# UART0 register map
Vendor: Texas Instruments
Peripheral module from a debugger description file (folder J7VCL).
Registers are 32-bit, access per field, reset 0x0 unless marked. A register's access mark holds for its fields unless they carry their own. Offsets are as the file gives them; lines under a group give offsets from that group; [hi:lo] are bit positions; {n}, {i} and the like mark numbered series; 'fields as' and 'values as' point back to an identical list; <NAME> marks a mode.

## UART0
0x00 UART_DLL — This register, with , stores the 14-bit divisor for generation of the baud clock in the baud rate generator. stores the most-significant part of the divisor. stores the least-significant part of the divisor.
  [7:0] CLOCK_LSB rw — Stores the 8-bit LSB divisor value
0x00 UART_RHR ro — The receiver section consists of the receiver holding register () and the receiver shift register. The is a 64-byte FIFO. The receiver shift register receives serial data from RX input. The data is converted to parallel data and moved to the . If the FIFO is disabled, location 0 of the FIFO stores the single data character. Note: If an overflow occurs, the data in the is not overwritten.
  [7:0] RHR — Receive holding register
0x00 UART_THR — The transmitter section consists of the transmit holding register () and the transmit shift register. The is a 64-byte FIFO. The local host (LH) writes data to the . The data is placed in the transmit shift register where it is shifted out serially on the TX output. If the FIFO is disabled, location 0 of the FIFO stores the data.
  [7:0] THR wo — Transmit holding register
0x04 UART_DLH — This register, with , stores the 14-bit divisor for generating the baud clock in the baud rate generator. DLH stores the most-significant part of the divisor. DLL stores the least-significant part of the divisor.
  [7:0] CLOCK_MSB rw — Stores the 8-bit MSB divisor value
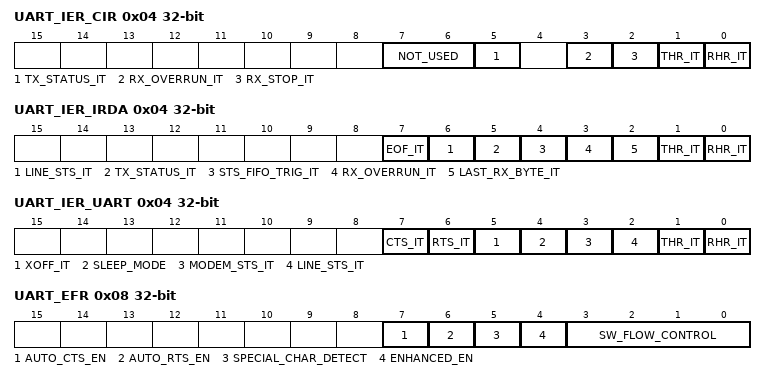
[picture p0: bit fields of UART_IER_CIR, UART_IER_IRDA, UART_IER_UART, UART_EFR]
0x04 UART_IER_CIR — There are 6 types of interrupt in these modes, TX status, status FIFO interrupt, RX overrun, last byte in RX FIFO, THR interrupt and RHR interrupt and they can be enabled/disabled individually. Notes: The RX_STOP_IT interrupt is generated based on the value set in the BOF Length register (). In IR-CIR mode, contrary to the IR-IRDA mode, the TX_STATUS_IT has only one meaning corresponding to the case [0] = 0.
  [7:6] NOT_USED rw, [5] TX_STATUS_IT rw, [3] RX_OVERRUN_IT rw, [2] RX_STOP_IT rw, [1] THR_IT rw, [0] RHR_IT rw
0x04 UART_IER_IRDA — There are 8 types of interrupt in these modes, received EOF, LSR interrupt, TX status, status FIFO interrupt, RX overrun, last byte in RX FIFO, THR interrupt and RHR interrupt and they can be enabled/disabled individually. Note: The TX_STATUS_IT interrupt reflects two possible conditions. The [0] should be read to determine the status in the event of this interrupt.
  [7] EOF_IT rw, [6] LINE_STS_IT rw, [5] TX_STATUS_IT rw, [4] STS_FIFO_TRIG_IT rw, [3] RX_OVERRUN_IT rw, [2] LAST_RX_BYTE_IT rw, [1] THR_IT rw, [0] RHR_IT rw
0x04 UART_IER_UART — Interrupt enable register The interrupt enable register () can be programmed to enable/disable any interrupt. There are seven types of interrupt in this mode: receiver error, interrupt, interrupt, XOFF received and CTS*/RTS* change of state from low to high. Each interrupt can be enabled/disabled individually. There is also a sleep mode enable bit.
  [7] CTS_IT rw, [6] RTS_IT rw, [5] XOFF_IT rw, [4] SLEEP_MODE rw, [3] MODEM_STS_IT rw, [2] LINE_STS_IT rw, [1] THR_IT rw, [0] RHR_IT rw
0x08 UART_EFR — Enhanced feature register This register enables or disables enhanced features. Most of the enhanced functions apply only to UART modes, but [4] enables write accesses to [5:4], the TX trigger level, which is also used in IrDA modes.
  [7] AUTO_CTS_EN rw — Auto-CTS enable bit
  [6] AUTO_RTS_EN rw — Auto-RTS enable bit
  [5] SPECIAL_CHAR_DETECT rw
  [4] ENHANCED_EN rw — Enhanced functions write enable bit
  [3:0] SW_FLOW_CONTROL rw — Combinations of software flow control can be selected by programming bit 3 - bit 0. See
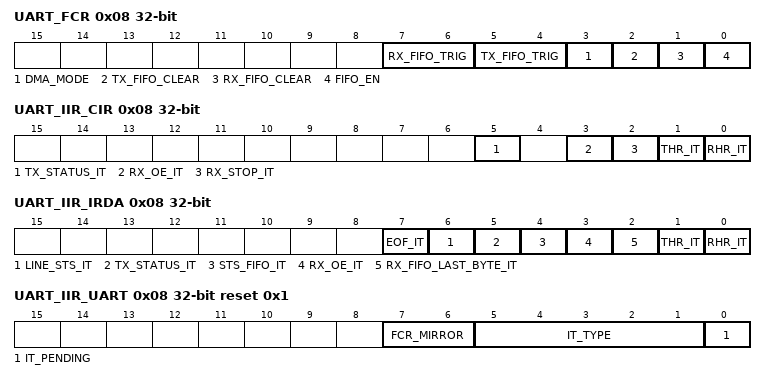
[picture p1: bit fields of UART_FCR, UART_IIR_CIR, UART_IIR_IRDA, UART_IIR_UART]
0x08 UART_FCR — FIFO control register Notes: Bits 4 and 5 can only be written to when [4] = 1. Bits 0 and 3 can be changed only when the baud clock is not running (DLL and DLH set to 0). See for [5:4] setting restriction when [6] = 1. See for [7:6] setting restriction when [7] = 1.
  [7:6] RX_FIFO_TRIG wo — Sets the trigger level for the RX FIFO: If
  [5:4] TX_FIFO_TRIG wo — Sets the trigger level for the TX FIFO: If
  [3] DMA_MODE wo — This register is considered if
  [2] TX_FIFO_CLEAR wo
  [1] RX_FIFO_CLEAR wo
  [0] FIFO_EN wo
0x08 UART_IIR_CIR ro — The interrupt line is activated whenever one of the 6 interrupts is active.
  [5] TX_STATUS_IT — Read 0h = TX status interrupt inactive
  [3] RX_OE_IT — Read 0h = RX overrun interrupt inactive
  [2] RX_STOP_IT — Read 0h = Receive stop interrupt inactive
  [1] THR_IT — Read 0h = THR interrupt inactive
  [0] RHR_IT — Read 0h = RHR interrupt inactive
0x08 UART_IIR_IRDA ro — The interrupt line is activated whenever one of the 8 interrupts is active.
  [7] EOF_IT, [6] LINE_STS_IT, [5] TX_STATUS_IT, [4] STS_FIFO_IT, [3] RX_OE_IT, [2] RX_FIFO_LAST_BYTE_IT, [1] THR_IT, [0] RHR_IT
0x08 UART_IIR_UART ro reset 0x1 — Interrupt identification register. The is a read-only register that provides the source of the interrupt in a prioritized manner.
  [7:6] FCR_MIRROR — Mirror the contents of
  [5:1] IT_TYPE — Read 0h = Modem interrupt. Priority = 4
  [0] IT_PENDING — Read 0h = An interrupt is pending.
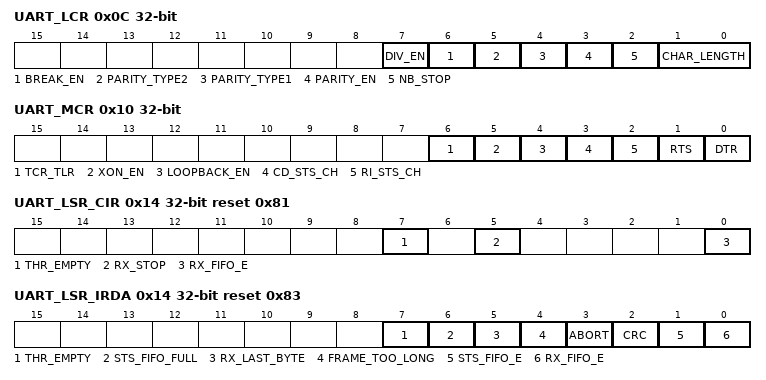
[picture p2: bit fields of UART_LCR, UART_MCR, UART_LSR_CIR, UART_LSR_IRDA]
0x0C UART_LCR — Line control register [6:0] define transmission and reception parameters. Note: When [6] is set to 1, the TX line is forced to 0 and remains in this state as long as [6] = 1.
  [7] DIV_EN rw
  [6] BREAK_EN rw — Break control bit
  [5] PARITY_TYPE2 rw — Selects the forced parity format (if
  [4] PARITY_TYPE1 rw
  [3] PARITY_EN rw — 0h = No parity
  [2] NB_STOP rw — Specifies the number of stop-bits
  [1:0] CHAR_LENGTH rw — Specifies the word length to be transmitted or received
0x10 UART_MCR — Modem control register [3:0] controls the interface with the modem, data set, or peripheral device that emulates the modem.
  [6] TCR_TLR rw — 0h = No action
  [5] XON_EN rw — 0h = Disable XON any function.
  [4] LOOPBACK_EN rw — 0h = Normal operating mode
  [3] CD_STS_CH rw — 0h = In loopback, forces DCD* input high and IRQ outputs to inactive state
  [2] RI_STS_CH rw — 0h = In loopback, forces RI* input high
  [1] RTS rw — In loopback, controls the
  [0] DTR rw — 0h = Force DTR* output to inactive (high).
0x10 UART_XON1_ADDR1 — UART mode: XON1 character, IrDA mode: ADDR1 address
  [7:0] XON_WORD1 rw — Stores the 8-bit XON1 character in UART modes and ADDR1 address 1 for IrDA modes
0x14 UART_LSR_CIR ro reset 0x81 — Line status register in CIR mode
  [7] THR_EMPTY — Read 0h = Transmit holding register (TX FIFO) is not empty.
  [5] RX_STOP — The RX_STOP is generated based on the value set in the BOF Length register (
  [0] RX_FIFO_E — Read 0h = At least one data character in the RX FIFO
0x14 UART_LSR_IRDA ro reset 0x83 — When the LSR is read, LSR[4:2] reflect the error bits [FL, CRC, ABORT] of the frame at the top of the STATUS FIFO (next frame status to be read).
  [7] THR_EMPTY — Read 0h = Transmit holding register (TX FIFO) is not empty.
  [6] STS_FIFO_FULL — Read 0h = Status FIFO not full
  [5] RX_LAST_BYTE — Read 0h = The RX FIFO (RHR) does not contain the last byte of the frame to be read.
  [4] FRAME_TOO_LONG — Read 0h = No frame-too-long error in frame
  [3] ABORT — Read 0h = No abort pattern error in frame
  [2] CRC — Read 0h = No CRC error in frame
  [1] STS_FIFO_E — Read 0h = Status FIFO not empty
  [0] RX_FIFO_E — Read 0h = No data in the RX FIFO
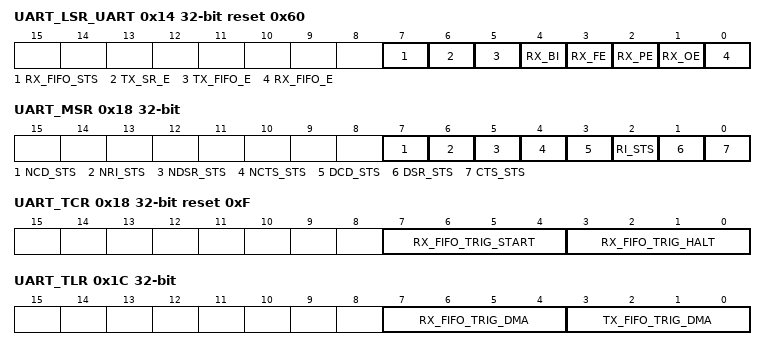
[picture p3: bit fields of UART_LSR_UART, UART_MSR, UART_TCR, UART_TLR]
0x14 UART_LSR_UART ro reset 0x60 — Line status register
  [7] RX_FIFO_STS — Read 0h = Normal operation
  [6] TX_SR_E — Read 0h = Transmitter hold (TX FIFO) and shift registers are not empty.
  [5] TX_FIFO_E — Read 0h = Transmit hold register (TX FIFO) is not empty.
  [4] RX_BI — Read 0h = No break condition
  [3] RX_FE — Read 0h = No framing error in data RX FIFO
  [2] RX_PE — Read 0h = No parity error in data from RX FIFO
  [1] RX_OE — Read 0h = No overrun error
  [0] RX_FIFO_E — Read 0h = No data in the RX FIFO
0x14 UART_XON2_ADDR2 — Stores the 8-bit XON2 character in UART moldes and ADDR2 address 2 for IrDA modes
  [7:0] XON_WORD2 rw — Stores the 8-bit XON2 character in UART modes and ADDR2 address 2 for IrDA modes
0x18 UART_MSR ro — Modem status register. UART mode only. This register provides information about the current state of the control lines from the modem, data set, or peripheral device to the LH. It also indicates when a control input from the modem changes state.
  [7] NCD_STS — This bit is the complement of the DCD* input. In loopback mode, it is equivalent to
  [6] NRI_STS — This bit is the complement of the RI* input. In loopback mode, it is equivalent to
  [5] NDSR_STS — This bit is the complement of the DSR* input. In loopback mode, it is equivalent to
  [4] NCTS_STS — This bit is the complement of the CTS* input. In loopback mode, it is equivalent to
  [3] DCD_STS — Indicates that DCD* input (or
  [2] RI_STS — Indicates that RI* input (or
  [1] DSR_STS
  [0] CTS_STS
0x18 UART_TCR reset 0xF — Transmission control register This register stores the RX FIFO threshold levels to start/stop transmission during hardware/software flow control. Notes: Trigger levels from 0 to 60 bytes are available with a granularity of 4. (Trigger level = 4 x [4-bit register value]) The programmer must ensure that [3:0] > [7:4] when auto-RTS or software flow control is enabled to avoid a mis-operation of the device. In FIFO interrupt mode with flow control, the programmer must ensure that the trigger level to halt transmission is greater than or equal to the RX FIFO trigger level ([7:4] or [7:6]); otherwise, FIFO operation stalls. In FIFO DMA mode with flow control, this concept does not exist because a DMA request is sent each time a byte is received.
  [7:4] RX_FIFO_TRIG_START rw — RX FIFO trigger level to RESTORE transmission (0 - 60)
  [3:0] RX_FIFO_TRIG_HALT rw — RX FIFO trigger level to HALT transmission (0 - 60)
0x18 UART_XOFF1 — UART mode XOFF1 character
  [7:0] XOFF_WORD1 rw — Stores the 8-bit XOFF1 character used in UART modes
0x1C UART_SPR — Scratchpad register This read/write register does not control the module. It is a scratchpad register to be used by the programmer to hold temporary data.
  [7:0] SPR_WORD rw — Scratchpad register
0x1C UART_TLR — Trigger level register This register stores the programmable transmit and RX FIFO trigger levels for DMA and IRQ generation.
  [7:4] RX_FIFO_TRIG_DMA rw — Receive FIFO trigger level
  [3:0] TX_FIFO_TRIG_DMA rw — Transmit FIFO trigger level
0x1C UART_XOFF2 — UART mode XOFF2 character
  [7:0] XOFF_WORD2 rw — Stores the 8-bit XOFF2 character used in UART modes.
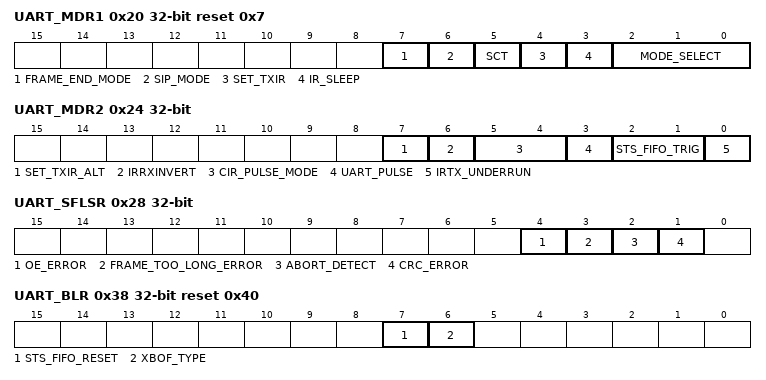
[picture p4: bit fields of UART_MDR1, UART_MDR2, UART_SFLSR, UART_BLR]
0x20 UART_MDR1 reset 0x7 — Mode definition register 1 The mode of operation can be programmed by writing to MDR1[2:0] and therefore the must be programmed on startup after configuration of the configuration registers (, , and ). The value of MDR1[2:0] must not be changed again during normal operation. Note: If the module is disabled by setting the MODE_SELECT field to 111, interrupt requests can still be generated unless disabled through the interrupt enable register (UART_IER). In this case, UART mode interrupts are visible. Reading the interrupt identification register (UART_IIR) shows UART mode interrupt flags.
  [7] FRAME_END_MODE rw — IrDA mode only
  [6] SIP_MODE rw — MIR/FIR modes only
  [5] SCT rw — Store and control the transmission.
  [4] SET_TXIR rw — Used to configure the infrared transceiver
  [3] IR_SLEEP rw — 0h = IrDA/CIR sleep mode disabled
  [2:0] MODE_SELECT rw — 0h = UART 16x mode
0x24 UART_MDR2 — Mode definition register 2 IR-IrDA and IR-CIR modes only. [0] describes the status of the interrupt in UART_IIR[5]. The IRTX_UNDERRUN bit should be read after an UART_IIR[5] TX_STATUS_IT interrupt. The bits [2:1] of this register set the trigger level for the frame status FIFO (8 entries) and must be programmed before the mode is programmed in [2:0]. Note: The [6] gives the flexibility to invert the RX pin in the UART to ensure that the protocol at the input of the transceiver module has the same polarity at module level. By default, the RX pin is inverted because most transceivers invert the IR receive pin.
  [7] SET_TXIR_ALT rw — Provide alternate function for
  [6] IRRXINVERT rw — IR mode only (IrDA and CIR). Invert RX pin in the module before the voting or sampling system logic of the infrared block. This does not affect the RX path in UART modem modes.
  [5:4] CIR_PULSE_MODE rw — CIR pulse modulation definition. Defines high level of the pulse width associated with a digit:
  [3] UART_PULSE rw — UART mode only. Allows pulse shaping in UART mode.
  [2:1] STS_FIFO_TRIG rw — IR-IrDA mode only. Frame status FIFO threshold select:
  [0] IRTX_UNDERRUN ro — IrDA transmission status interrupt. When the UART_IIR[5] interrupt occurs, the meaning of the interrupt is:
0x28 UART_SFLSR ro — Status FIFO line status register IrDA modes only. Reading this register effectively reads frame status information from the status FIFO (this register does not physically exist). Reading this register increments the status FIFO read pointer ( and must be read first).
  [4] OE_ERROR — Read 1h = Overrun error in RX FIFO when frame at top of RX FIFO was received
  [3] FRAME_TOO_LONG_ERROR — Read 1h = Frame-length too long error in frame at top of RX FIFO
  [2] ABORT_DETECT — Read 1h = Abort pattern detected in frame at top of RX FIFO
  [1] CRC_ERROR — Read 1h = CRC error in frame at top of RX FIFO
0x28 UART_TXFLL — Transmit frame length register low IrDA modes only. The and registers hold the 13-bit transmit frame length (expressed in bytes). holds the LSBs and holds the MSBs. The frame length value is used if the frame length method of frame closing is used.
  [7:0] TXFLL wo — LSB register used to specify the frame length
0x2C UART_RESUME ro — IR-IrDA and IR-CIR modes only. This register is used to clear internal flags, which halt transmission/reception when an underrun/overrun error occurs. Reading this register resumes the halted operation. This register does not physically exist and reads always as 0x00.
  [7:0] RESUME — Dummy read to restart the TX or RX
0x2C UART_TXFLH — Transmit frame length register high IrDA modes only. The and registers hold the 13-bit transmit frame length (expressed in bytes). holds the LSBs and holds the MSBs. The frame length value is used if the frame length method of frame closing is used.
  [4:0] TXFLH wo — MSB register used to specify the frame length
0x30 UART_RXFLL — Received frame length register low IrDA modes only. The and registers hold the 12-bit receive maximum frame length. holds the LSBs and holds the MSBs. If the intended maximum receive frame length is n bytes, program the and registers to be n + 3 in SIR or MIR modes and n + 6 in FIR mode (+3 and +6 are the result of frame format with CRC and stop flag; 2 bytes are associated with the FIR stop flag).
  [7:0] RXFLL wo — LSB register used to specify the frame length in reception
0x30 UART_SFREGL ro — Status FIFO register low IrDA modes only. The frame lengths of received frames are written into the status FIFO. This information can be read by reading the and registers (these registers do not physically exist). The LSBs are read from and the MSBs are read from . Reading these registers does not alter the status FIFO read pointer. These registers should be read before the pointer is incremented by reading the register.
  [7:0] SFREGL — LSB part of the frame length
0x34 UART_RXFLH — Received frame length register high IrDA modes only. The and registers hold the 12-bit receive maximum frame length. holds the LSBs and holds the MSBs. If the intended maximum receive frame length is n bytes, program the and to be n + 3 in SIR or MIR modes and n + 6 in FIR mode (+3 and +6 are the result of frame format with CRC and stop flag; 2 bytes are associated with the FIR stop flag).
  [3:0] RXFLH wo — MSB register used to specify the frame length in reception
0x34 UART_SFREGH ro — Status FIFO register high IrDA modes only. The frame lengths of received frames are written into the status FIFO. This information can be read by reading the and registers (these registers do not physically exist). The LSBs are read from and the MSBs are read from . Reading these registers does not alter the status FIFO read pointer. These registers should be read before the pointer is incremented by reading the register.
  [3:0] SFREGH — MSB part of the frame length
0x38 UART_BLR access not given reset 0x40 — BOF control register IrDA modes only. The [6] bit selects whether 0xC0 or 0xFF start patterns are to be used, when multiple start flags are required in SIR mode. If only one start flag is required, this is always 0xC0. If n start flags are required, (-1) 0xC0 or (-1) 0xFF flags are sent, followed by a single 0xC0 flag (immediately preceding the first data byte).
  [7] STS_FIFO_RESET — Status FIFO reset. This bit is self-clearing. (access RW1S)
  [6] XBOF_TYPE rw — SIR xBOF select
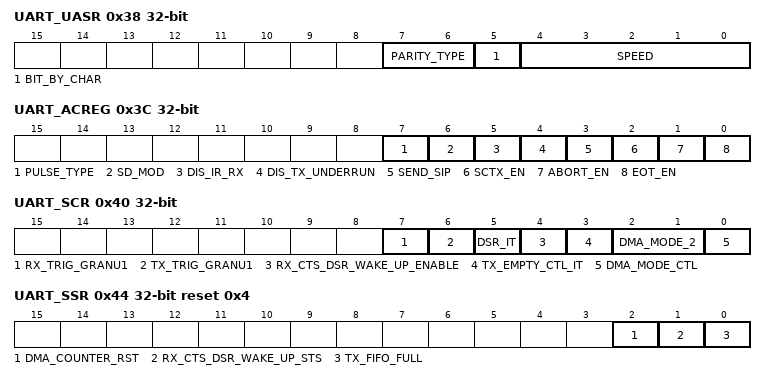
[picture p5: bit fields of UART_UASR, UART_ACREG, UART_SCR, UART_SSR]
0x38 UART_UASR ro — UART autobauding status register UART autobauding mode only. This status register returns the speed, the number of bits by characters, and the type of the parity in UART autobauding mode. In autobauding mode, the input frequency of the UART modem must be fixed to 48 MHz. Any other module clock frequency results in incorrect baud rate recognition. Note: When the UART is in autobauding mode, this register, instead of the , , and registers, is used to set up transmission according to the characteristics of the previous reception. To reset the autobauding hardware (to start a new AT detection), set [2:0] to 111 (reset value), then set [2:1] to 010 (UART in autobaud mode). To set the UART to standard mode (no autobaud), set [2:1] to 000.
  [7:6] PARITY_TYPE — Read 0h = No parity identified
  [5] BIT_BY_CHAR — Read 0h = 7-bit character identified
  [4:0] SPEED — Used to report the speed identified
0x3C UART_ACREG access not given — Auxiliary control register. IR-IrDA and IR-CIR modes only.
  [7] PULSE_TYPE rw — SIR pulse width select
  [6] SD_MOD rw — Primary output used to configure transceivers. Connected to the SD/MODE input pin of IrDA transceivers.
  [5] DIS_IR_RX rw — 0h = Normal operation (RX input automatically disabled during transmit but enabled outside of transmit operation)
  [4] DIS_TX_UNDERRUN rw — It is recommended to disable TX FIFO underrun capability by masking corresponding underrun interrupt. When disabling underrun by setting
  [3] SEND_SIP — MIR/FIR modes only. Send serial infrared interaction pulse (SIP). If this bit is set during an MIR/FIR transmission, the SIP is sent at the end of it. This bit is cleared automatically at the end of the SIP transmission. (access RW1S)
  [2] SCTX_EN — Store and controlled TX start. When (access RW1S)
  [1] ABORT_EN rw — Frame abort. The LH can intentionally abort transmission of a frame by writing 1 to this bit. Neither the end flag nor the CRC bits are appended to the frame. If TX FIFO is not empty and
  [0] EOT_EN — EOT (end of transmission) bit. The LH writes 1 to this bit just before it writes the last byte to the TX FIFO in set-EOT bit frame closing method. This bit is cleared automatically when the LH writes to the THR (TX FIFO). (access RW1S)
0x40 UART_SCR — Supplementary control register Note: Bit 4 enables the wake-up interrupt, but this interrupt is not mapped into the UART_IIR register. Therefore, when an interrupt occurs and there is no interrupt pending in the UART_IIR register, the [1] bit must be checked. To clear the wake-up interrupt, bit [4] must be reset to 0.
  [7] RX_TRIG_GRANU1 rw — 0h = Disables the granularity of 1 for trigger RX level
  [6] TX_TRIG_GRANU1 rw — 0h = Disables the granularity of 1 for trigger TX level
  [5] DSR_IT rw — 0h = Disables DSR* interrupt
  [4] RX_CTS_DSR_WAKE_UP_ENABLE rw — 0h = Disables the wake-up interrupt and clears SSR[1]
  [3] TX_EMPTY_CTL_IT rw — 0h = Normal mode for THR interrupt
  [2:1] DMA_MODE_2 rw — Used to specify the DMA mode valid if the
  [0] DMA_MODE_CTL rw — 0h = The DMA_MODE is set with
0x44 UART_SSR reset 0x4 — Supplementary status register Note: Bit 1 is reset only when [4] is reset to 0.
  [2] DMA_COUNTER_RST rw — 0h = The DMA counter will not be reset if the corresponding FIFO is reset (through
  [1] RX_CTS_DSR_WAKE_UP_STS ro — Read 0h = No falling edge event on RX, CTS*, and DSR*
  [0] TX_FIFO_FULL ro — Read 0h = TX FIFO is not full.
0x48 UART_EBLR — BOF length register IR-IrDA and IR-CIR modes only. In IR-IrDA SIR operation, this register specifies the number of BOF + xBOFs to transmit. Value set into this register must account for the BOF character; therefore, to send only one BOF with no XBOF, this register must be set to 1. To send one BOF with N XBOF, this register must be set to N + 1. The value 0 sends 1 BOF plus 255 XBOF. In IR-IrDA MIR mode, this register specifies the number of additional start flags (MIR protocol mandates a minimum of 2 start flags). In IR-CIR mode, this register specifies the number of consecutive 0s to be received before generating the RX_STOP interrupt (UART_IIR[2]). All received 0s are stored in the RX FIFO. When the register is set to 0, this feature is deactivated and always in reception state, which can be disabled by setting the [5] to 1. Note: If the RX_STOP interrupt occurs before a byte boundary, the remaining bits of the last byte are filled with 0s and passed into the RX FIFO.
  [7:0] EBLR rw — IR-IrDA mode: This register allows definition of up to 176 xBOFs, the maximum required by IrDA specification.
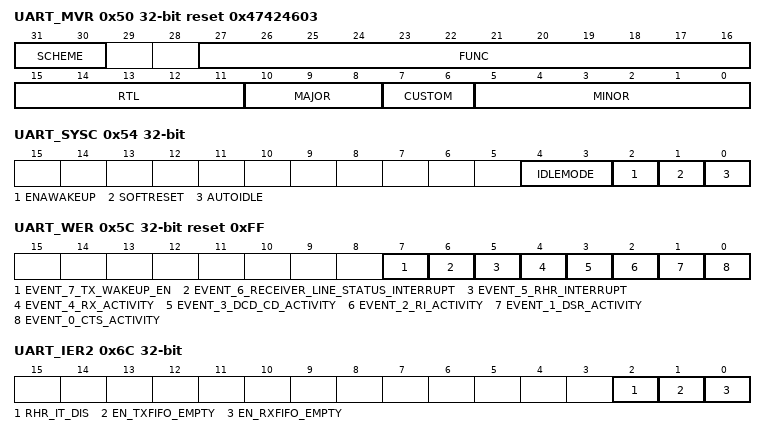
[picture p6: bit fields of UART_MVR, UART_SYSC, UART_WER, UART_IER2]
0x50 UART_MVR ro reset 0x47424603 — Module version register The reset value is fixed by hardware and corresponds to the RTL revision of this module. A reset has no effect on the value returned.
  [31:30] SCHEME — Scheme revision number of module
  [27:16] FUNC — Function revision number of module
  [15:11] RTL — Rtl revision number of module
  [10:8] MAJOR — Major revision number of the module
  [7:6] CUSTOM — Custom revision number of the module
  [5:0] MINOR — Minor revision number of the module
0x54 UART_SYSC — System configuration register The AUTOIDLE bit controls a power-saving technique to reduce the logic power consumption of the open-core protocol (OCP) interface. When the feature is enabled, the clock is gated off until an OCP command for this device is detected. When the software reset bit is set high, it causes a full device reset.
  [4:3] IDLEMODE rw — Power management req/ack control ref: OCP Design Guidelines Version 1.1
  [2] ENAWAKEUP rw — Wake-up feature control
  [1] SOFTRESET wo — Software reset. Set this bit to 1 to trigger a module reset. This bit is automatically reset by the hardware. Read returns 0.
  [0] AUTOIDLE rw — Internal OCP clock gating strategy
0x58 UART_SYSS ro — System status register
  [0] RESETDONE — Internal reset monitoring
0x5C UART_WER reset 0xFF — Wake-up enable register The UART wake-up enable register is used to mask and unmask a UART event that would subsequently notify the system. An event is any activity in the logic that could cause an interrupt and/or an activity that would require the system to wake up. Even if the wakeup is disabled for certain events, if these events are also an interrupt to the UART, the UART registers the interrupt.
  [7] EVENT_7_TX_WAKEUP_EN rw — 0h = Event is not allowed to wake up the system.
  [6] EVENT_6_RECEIVER_LINE_STATUS_INTERRUPT rw — 0h = Event is not allowed to wake up the system.
  [5] EVENT_5_RHR_INTERRUPT rw — 0h = Event is not allowed to wake up the system.
  [4] EVENT_4_RX_ACTIVITY rw — 0h = Event is not allowed to wake up the system.
  [3] EVENT_3_DCD_CD_ACTIVITY rw — 0h = Event is not allowed to wake up the system
  [2] EVENT_2_RI_ACTIVITY rw — 0h = Event is not allowed to wake up the system.
  [1] EVENT_1_DSR_ACTIVITY rw — 0h = Event is not allowed to wake up the system.
  [0] EVENT_0_CTS_ACTIVITY rw — 0h = Event is not allowed to wake up the system.
0x60 UART_CFPS reset 0x69 — Carrier frequency prescaler Because the consumer IR works at modulation rates of 30 to 56.8 kHz, the 48-MHz clock must be prescaled before the clock can drive the IR logic. This register sets the divisor rate to give a range to accommodate the remote-control requirements in baud multiples of 12x. The value of the CFPS at reset is 0105 decimal, which equals 38.1 kHz output from starting conditions. The 48-MHz carrier is prescaled by the CFPS, which is then divided by the 12x baud multiple.
  [7:0] CFPS rw — System clock frequency prescaler at (12x multiple). Examples for CFPS values:
0x64 UART_RXFIFO_LVL ro — Level of the RX FIFO
  [7:0] RXFIFO_LVL — Shows the number of received bytes in the RX FIFO
0x68 UART_TXFIFO_LVL ro — Level of the TX FIFO
  [7:0] TXFIFO_LVL — Shows the number of written bytes in the TX FIFO
0x6C UART_IER2 — Enables RX/TX FIFOs empty corresponding interrupts
  [2] RHR_IT_DIS rw — 0h = Enables the RHR interrupt.
  [1] EN_TXFIFO_EMPTY rw — Enables TX FIFO empty corresponding interrupt
  [0] EN_RXFIFO_EMPTY rw — Enables RX FIFO empty corresponding interrupt
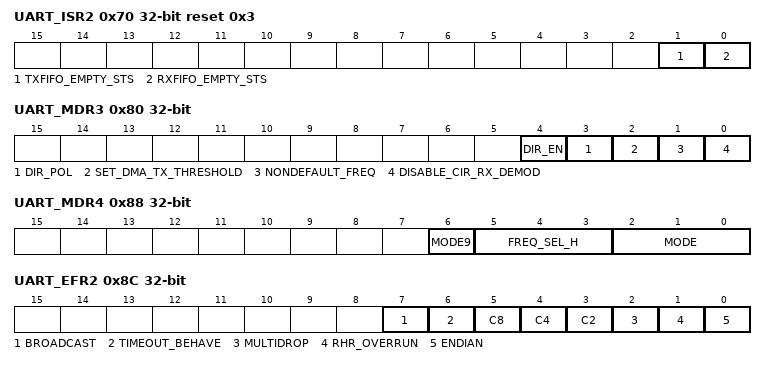
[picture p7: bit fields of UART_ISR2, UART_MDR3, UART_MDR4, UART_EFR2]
0x70 UART_ISR2 access not given reset 0x3 — Status of RX/TX FIFOs empty corresponding interrupts
  [1] TXFIFO_EMPTY_STS — Used to generate interrupt if the TX_FIFO is empty (software flow control) (access RW1C)
  [0] RXFIFO_EMPTY_STS — Used to generate interrupt if the RX_FIFO is empty (software flow control) (access RW1C)
0x74 UART_FREQ_SEL reset 0x1A — Sample per bit selector
  [7:0] FREQ_SEL rw — Sets the sample per bit if nondefault frequency is used.
0x78 UART_ABAUD_1ST_CHAR ro — Unused
0x7C UART_BAUD_2ND_CHAR ro — Unused
0x80 UART_MDR3 — Mode definition register 3
  [4] DIR_EN rw — RS-485 External Transceiver Direction Enable
  [3] DIR_POL rw — RS-485 External Transceiver Direction Polarity. 0h = TX: RTS=0, RX: RTS=1. 1h = TX: RTS=1, RX: RTS=0
  [2] SET_DMA_TX_THRESHOLD rw — Enable to set different TXDMA threshold in
  [1] NONDEFAULT_FREQ rw — Used to enable the NONDEFAULT fclk frequencies.
  [0] DISABLE_CIR_RX_DEMOD rw — Used to enable CIR RX demodulation.
0x84 UART_TX_DMA_THRESHOLD — Use to manually set the TX DMA threshold level. [2] SET_TX_DMA_THRESHOLD must be 1 and must be value + tx_trigger_level = 64 (TX FIFO size). If not, 64-tx_trigger_level will be used without modifying the value of this register.
  [5:0] TX_DMA_THRESHOLD rw — Used to manually set the TX DMA threshold level
0x88 UART_MDR4 — Mode definition register 4
  [6] MODE9 rw — 9-bit character length When '1', overrides character length setting in UART_LCR
  [5:3] FREQ_SEL_H rw — Upper 3 bits of
  [2:0] MODE rw — New modes [when set, overrides
0x8C UART_EFR2 — Enhanced Features Register 2
  [7] BROADCAST rw — Enables broadcast address matching in multi-drop address match mode
  [6] TIMEOUT_BEHAVE rw — Specifies how timeout is measured
  [5] C8 rw — Value for ISO 7816 C8 pin for software control
  [4] C4 rw — Value for ISO 7816 C4 pin for software control
  [3] C2 rw — Value for ISO 7816 reset pin [software controllable]
  [2] MULTIDROP rw — Enables parity Multi-drop mode [overrides
  [1] RHR_OVERRUN rw
  [0] ENDIAN rw — Endianness
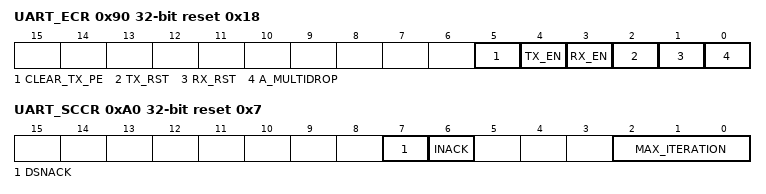
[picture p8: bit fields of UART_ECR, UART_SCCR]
0x90 UART_ECR reset 0x18 — Enhanced Control register
  [5] CLEAR_TX_PE wo — Write 1h = to clear parity error from the Transmitter to allow it to continue to try sending data [ISO7816 transmit only]
  [4] TX_EN rw — Enables/Disables the transmitter
  [3] RX_EN rw — Enables/Disables the receiver
  [2] TX_RST wo — Writing 1h = resets the transmitter
  [1] RX_RST wo — Writing 1h = resets the receiver
  [0] A_MULTIDROP wo — In multi-drop mode, when written with the value '1' causes the next byte written into
0x94 UART_TIMEGUARD — Timeguard
  [7:0] TIMEGUARD rw — Specifies the amount of idle baud clocks [transmitter bit period] to insert between transmitted bytes, useful when comunicating with slower devices
0x98 UART_TIMEOUTL — Timeout lower byte
  [7:0] TIMEOUT_L rw — Custom timeout period in baud clocks, to override the internal value, when different from 0 [Lower byte of the 16 bit value]
0x9C UART_TIMEOUTH — Timeout higher byte
  [7:0] TIMEOUT_H rw — Custom timeout period in baud clocks, to override the internal value, when different from 0 [Higher byte of the 16 bit value]
0xA0 UART_SCCR reset 0x7 — Smartcard (ISO7816) mode Control Register
  [7] DSNACK rw — Applies Max_Iteration to receiver aswell - when maximum number of NACKs have been returned, the receiver will accept the data regardless of error The data will be loaded into the receiver FIFO and PE will be set when reading it
  [6] INACK rw — Inhibit NACK when receiving, even if an error is received The data will be loaded into the receiver FIFO and PE will be set when reading it
  [2:0] MAX_ITERATION rw — Number of times to repeat transmitted character, if the receiver did not acknowledge If not acknowledged after the max value is reached, the UART transmitter will set parity error, stop and not continue until it is cleared
0xA4 UART_ERHR ro — Extended Receive Holding Register
  [8:0] ERHR — Extended Receive Holding Register - allows accessing the full 9bit
0xA4 UART_ETHR — Extended Transmit Holding Register
  [8:0] ETHR wo — Extended Transmit Holding Register - allows writing the full 9bit
0xA8 UART_MAR — Multidrop Address Register
  [7:0] ADDRESS rw — Multidrop match address value
0xAC UART_MMR — Multidrop Mask Register
  [7:0] MASK rw — Address match masking value ? writing a 0 to a bit means that the corresponding address bit will be ignored in matching
0xB0 UART_MBR — Multidrop Broadcast Address Register
  [7:0] BROADCAST_ADDRESS rw — Broadcast address for address matching
